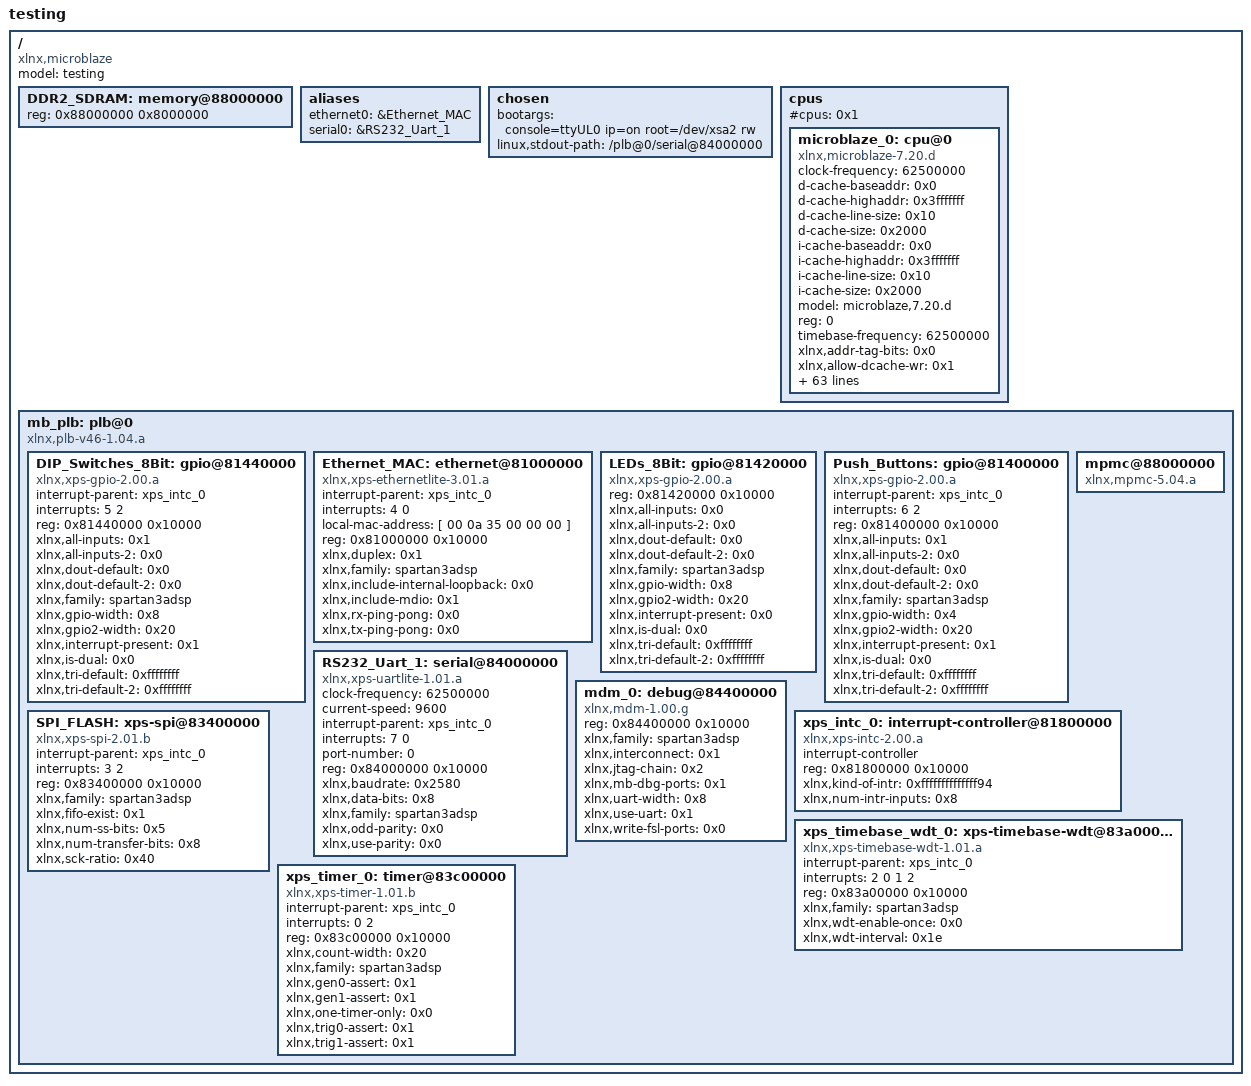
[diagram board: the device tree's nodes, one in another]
/*
 * Device Tree Generator version: 1.1
 *
 * (C) Copyright 2007-2008 Xilinx, Inc.
 * (C) Copyright 2007-2009 Michal Simek
 *
 * Michal SIMEK <monstr@monstr.eu>
 *
 * This program is free software; you can redistribute it and/or
 * modify it under the terms of the GNU General Public License as
 * published by the Free Software Foundation; either version 2 of
 * the License, or (at your option) any later version.
 *
 * This program is distributed in the hope that it will be useful,
 * but WITHOUT ANY WARRANTY; without even the implied warranty of
 * MERCHANTABILITY or FITNESS FOR A PARTICULAR PURPOSE. See the
 * GNU General Public License for more details.
 *
 * You should have received a copy of the GNU General Public License
 * along with this program; if not, write to the Free Software
 * Foundation, Inc., 59 Temple Place, Suite 330, Boston,
 * MA 02111-1307 USA
 *
 * CAUTION: This file is automatically generated by libgen.
 * Version: Xilinx EDK 11.5 EDK_LS5.70
 *
 * XPS project directory: mb-spartan1800
 */

/dts-v1/;
/ {
	#address-cells = <1>;
	#size-cells = <1>;
	compatible = "xlnx,microblaze";
	model = "testing";
	DDR2_SDRAM: memory@88000000 {
		device_type = "memory";
		reg = < 0x88000000 0x8000000 >;
	} ;
	aliases {
		ethernet0 = &Ethernet_MAC;
		serial0 = &RS232_Uart_1;
	} ;
	chosen {
		bootargs = "console=ttyUL0 ip=on root=/dev/xsa2 rw";
		linux,stdout-path = "/plb@0/serial@84000000";
	} ;
	cpus {
		#address-cells = <1>;
		#cpus = <0x1>;
		#size-cells = <0>;
		microblaze_0: cpu@0 {
			clock-frequency = <62500000>;
			compatible = "xlnx,microblaze-7.20.d";
			d-cache-baseaddr = <0x0>;
			d-cache-highaddr = <0x3fffffff>;
			d-cache-line-size = <0x10>;
			d-cache-size = <0x2000>;
			device_type = "cpu";
			i-cache-baseaddr = <0x0>;
			i-cache-highaddr = <0x3fffffff>;
			i-cache-line-size = <0x10>;
			i-cache-size = <0x2000>;
			model = "microblaze,7.20.d";
			reg = <0>;
			timebase-frequency = <62500000>;
			xlnx,addr-tag-bits = <0x0>;
			xlnx,allow-dcache-wr = <0x1>;
			xlnx,allow-icache-wr = <0x1>;
			xlnx,area-optimized = <0x0>;
			xlnx,cache-byte-size = <0x2000>;
			xlnx,d-lmb = <0x1>;
			xlnx,d-opb = <0x0>;
			xlnx,d-plb = <0x1>;
			xlnx,data-size = <0x20>;
			xlnx,dcache-addr-tag = <0x0>;
			xlnx,dcache-always-used = <0x0>;
			xlnx,dcache-byte-size = <0x2000>;
			xlnx,dcache-interface = <0x0>;
			xlnx,dcache-line-len = <0x4>;
			xlnx,dcache-use-fsl = <0x1>;
			xlnx,dcache-use-writeback = <0x0>;
			xlnx,debug-enabled = <0x1>;
			xlnx,div-zero-exception = <0x0>;
			xlnx,dopb-bus-exception = <0x0>;
			xlnx,dynamic-bus-sizing = <0x1>;
			xlnx,edge-is-positive = <0x1>;
			xlnx,family = "spartan3adsp";
			xlnx,fpu-exception = <0x0>;
			xlnx,fsl-data-size = <0x20>;
			xlnx,fsl-exception = <0x0>;
			xlnx,fsl-links = <0x0>;
			xlnx,i-lmb = <0x1>;
			xlnx,i-opb = <0x0>;
			xlnx,i-plb = <0x1>;
			xlnx,icache-always-used = <0x0>;
			xlnx,icache-interface = <0x0>;
			xlnx,icache-line-len = <0x4>;
			xlnx,icache-use-fsl = <0x1>;
			xlnx,ill-opcode-exception = <0x0>;
			xlnx,instance = "microblaze_0";
			xlnx,interconnect = <0x1>;
			xlnx,interrupt-is-edge = <0x0>;
			xlnx,iopb-bus-exception = <0x0>;
			xlnx,mmu-dtlb-size = <0x4>;
			xlnx,mmu-itlb-size = <0x2>;
			xlnx,mmu-tlb-access = <0x3>;
			xlnx,mmu-zones = <0x10>;
			xlnx,number-of-pc-brk = <0x1>;
			xlnx,number-of-rd-addr-brk = <0x0>;
			xlnx,number-of-wr-addr-brk = <0x0>;
			xlnx,opcode-0x0-illegal = <0x0>;
			xlnx,pvr = <0x0>;
			xlnx,pvr-user1 = <0x0>;
			xlnx,pvr-user2 = <0x0>;
			xlnx,reset-msr = <0x0>;
			xlnx,sco = <0x0>;
			xlnx,unaligned-exceptions = <0x0>;
			xlnx,use-barrel = <0x0>;
			xlnx,use-dcache = <0x0>;
			xlnx,use-div = <0x0>;
			xlnx,use-ext-brk = <0x1>;
			xlnx,use-ext-nm-brk = <0x1>;
			xlnx,use-extended-fsl-instr = <0x0>;
			xlnx,use-fpu = <0x0>;
			xlnx,use-hw-mul = <0x1>;
			xlnx,use-icache = <0x0>;
			xlnx,use-interrupt = <0x1>;
			xlnx,use-mmu = <0x3>;
			xlnx,use-msr-instr = <0x1>;
			xlnx,use-pcmp-instr = <0x1>;
		} ;
	} ;
	mb_plb: plb@0 {
		#address-cells = <1>;
		#size-cells = <1>;
		compatible = "xlnx,plb-v46-1.04.a", "xlnx,plb-v46-1.00.a", "simple-bus";
		ranges ;
		DIP_Switches_8Bit: gpio@81440000 {
			compatible = "xlnx,xps-gpio-2.00.a", "xlnx,xps-gpio-1.00.a";
			interrupt-parent = <&xps_intc_0>;
			interrupts = < 5 2 >;
			reg = < 0x81440000 0x10000 >;
			xlnx,all-inputs = <0x1>;
			xlnx,all-inputs-2 = <0x0>;
			xlnx,dout-default = <0x0>;
			xlnx,dout-default-2 = <0x0>;
			xlnx,family = "spartan3adsp";
			xlnx,gpio-width = <0x8>;
			xlnx,gpio2-width = <0x20>;
			xlnx,interrupt-present = <0x1>;
			xlnx,is-dual = <0x0>;
			xlnx,tri-default = <0xffffffff>;
			xlnx,tri-default-2 = <0xffffffff>;
		} ;
		Ethernet_MAC: ethernet@81000000 {
			compatible = "xlnx,xps-ethernetlite-3.01.a", "xlnx,xps-ethernetlite-1.00.a";
			device_type = "network";
			interrupt-parent = <&xps_intc_0>;
			interrupts = < 4 0 >;
			local-mac-address = [ 00 0a 35 00 00 00 ];
			reg = < 0x81000000 0x10000 >;
			xlnx,duplex = <0x1>;
			xlnx,family = "spartan3adsp";
			xlnx,include-internal-loopback = <0x0>;
			xlnx,include-mdio = <0x1>;
			xlnx,rx-ping-pong = <0x0>;
			xlnx,tx-ping-pong = <0x0>;
		} ;
		LEDs_8Bit: gpio@81420000 {
			compatible = "xlnx,xps-gpio-2.00.a", "xlnx,xps-gpio-1.00.a";
			reg = < 0x81420000 0x10000 >;
			xlnx,all-inputs = <0x0>;
			xlnx,all-inputs-2 = <0x0>;
			xlnx,dout-default = <0x0>;
			xlnx,dout-default-2 = <0x0>;
			xlnx,family = "spartan3adsp";
			xlnx,gpio-width = <0x8>;
			xlnx,gpio2-width = <0x20>;
			xlnx,interrupt-present = <0x0>;
			xlnx,is-dual = <0x0>;
			xlnx,tri-default = <0xffffffff>;
			xlnx,tri-default-2 = <0xffffffff>;
		} ;
		Push_Buttons: gpio@81400000 {
			compatible = "xlnx,xps-gpio-2.00.a", "xlnx,xps-gpio-1.00.a";
			interrupt-parent = <&xps_intc_0>;
			interrupts = < 6 2 >;
			reg = < 0x81400000 0x10000 >;
			xlnx,all-inputs = <0x1>;
			xlnx,all-inputs-2 = <0x0>;
			xlnx,dout-default = <0x0>;
			xlnx,dout-default-2 = <0x0>;
			xlnx,family = "spartan3adsp";
			xlnx,gpio-width = <0x4>;
			xlnx,gpio2-width = <0x20>;
			xlnx,interrupt-present = <0x1>;
			xlnx,is-dual = <0x0>;
			xlnx,tri-default = <0xffffffff>;
			xlnx,tri-default-2 = <0xffffffff>;
		} ;
		RS232_Uart_1: serial@84000000 {
			clock-frequency = <62500000>;
			compatible = "xlnx,xps-uartlite-1.01.a", "xlnx,xps-uartlite-1.00.a";
			current-speed = <9600>;
			device_type = "serial";
			interrupt-parent = <&xps_intc_0>;
			interrupts = < 7 0 >;
			port-number = <0>;
			reg = < 0x84000000 0x10000 >;
			xlnx,baudrate = <0x2580>;
			xlnx,data-bits = <0x8>;
			xlnx,family = "spartan3adsp";
			xlnx,odd-parity = <0x0>;
			xlnx,use-parity = <0x0>;
		} ;
		SPI_FLASH: xps-spi@83400000 {
			compatible = "xlnx,xps-spi-2.01.b", "xlnx,xps-spi-2.00.a";
			interrupt-parent = <&xps_intc_0>;
			interrupts = < 3 2 >;
			reg = < 0x83400000 0x10000 >;
			xlnx,family = "spartan3adsp";
			xlnx,fifo-exist = <0x1>;
			xlnx,num-ss-bits = <0x5>;
			xlnx,num-transfer-bits = <0x8>;
			xlnx,sck-ratio = <0x40>;
		} ;
		mdm_0: debug@84400000 {
			compatible = "xlnx,mdm-1.00.g";
			reg = < 0x84400000 0x10000 >;
			xlnx,family = "spartan3adsp";
			xlnx,interconnect = <0x1>;
			xlnx,jtag-chain = <0x2>;
			xlnx,mb-dbg-ports = <0x1>;
			xlnx,uart-width = <0x8>;
			xlnx,use-uart = <0x1>;
			xlnx,write-fsl-ports = <0x0>;
		} ;
		mpmc@88000000 {
			#address-cells = <1>;
			#size-cells = <1>;
			compatible = "xlnx,mpmc-5.04.a";
		} ;
		xps_intc_0: interrupt-controller@81800000 {
			#interrupt-cells = <0x2>;
			compatible = "xlnx,xps-intc-2.00.a", "xlnx,xps-intc-1.00.a";
			interrupt-controller ;
			reg = < 0x81800000 0x10000 >;
			xlnx,kind-of-intr = <0xffffffffffffff94>;
			xlnx,num-intr-inputs = <0x8>;
		} ;
		xps_timebase_wdt_0: xps-timebase-wdt@83a00000 {
			compatible = "xlnx,xps-timebase-wdt-1.01.a";
			interrupt-parent = <&xps_intc_0>;
			interrupts = < 2 0 1 2 >;
			reg = < 0x83a00000 0x10000 >;
			xlnx,family = "spartan3adsp";
			xlnx,wdt-enable-once = <0x0>;
			xlnx,wdt-interval = <0x1e>;
		} ;
		xps_timer_0: timer@83c00000 {
			compatible = "xlnx,xps-timer-1.01.b", "xlnx,xps-timer-1.00.a";
			interrupt-parent = <&xps_intc_0>;
			interrupts = < 0 2 >;
			reg = < 0x83c00000 0x10000 >;
			xlnx,count-width = <0x20>;
			xlnx,family = "spartan3adsp";
			xlnx,gen0-assert = <0x1>;
			xlnx,gen1-assert = <0x1>;
			xlnx,one-timer-only = <0x0>;
			xlnx,trig0-assert = <0x1>;
			xlnx,trig1-assert = <0x1>;
		} ;
	} ;
}  ;
